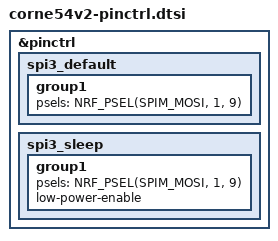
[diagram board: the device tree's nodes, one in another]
/*
 * Copyright (c) 2023 The ZMK Contributors
 * SPDX-License-Identifier: MIT
 */

&pinctrl {
    spi3_default: spi3_default {
        group1 {
            psels = <NRF_PSEL(SPIM_MOSI, 1, 9)>; // WS2812_VEXT_DATA
        };
    };

    spi3_sleep: spi3_sleep {
        group1 {
            psels = <NRF_PSEL(SPIM_MOSI, 1, 9)>;
            low-power-enable;
        };
    };
};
